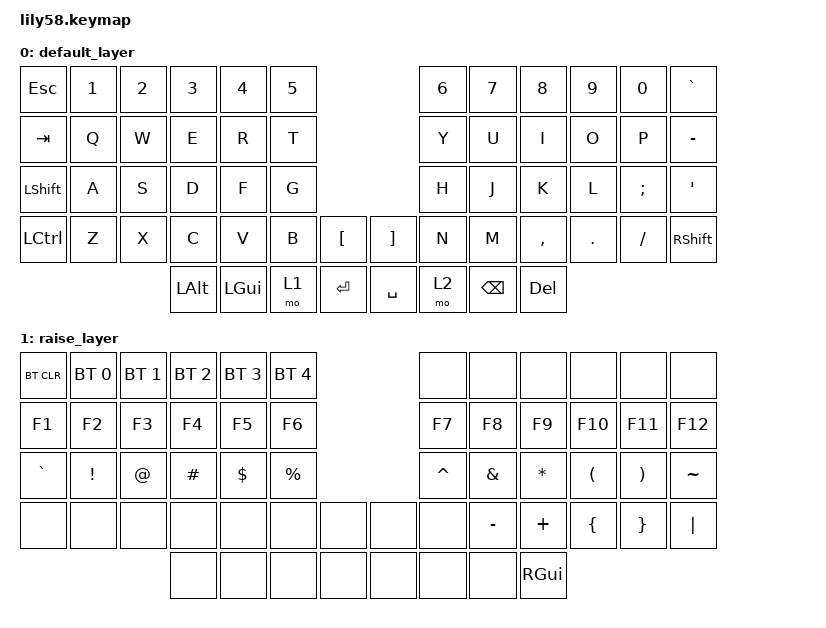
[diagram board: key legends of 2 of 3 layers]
/*
 * Copyright (c) 2020 The ZMK Contributors
 *
 * SPDX-License-Identifier: MIT
 */

#include <behaviors.dtsi>
#include <dt-bindings/zmk/keys.h>
#include <dt-bindings/zmk/bt.h>
#include <dt-bindings/zmk/ext_power.h>
// https://zmk.dev/docs/keymaps/list-of-keycodes

/ {
macros {
        zed_em_kay: zed_em_kay {
            compatible = "zmk,behavior-macro";
            #binding-cells = <0>;
            bindings
                = <&macro_press &kp LSHFT>
                , <&macro_tap &kp Z &kp M &kp K>
                , <&macro_release &kp LSHFT>
                ;
        };
    };




    keymap {
        compatible = "zmk,keymap";

        default_layer {
// ------------------------------------------------------------------------------------------------------------
// |  ESC  |  1  |  2  |  3   |  4   |  5   |                   |  6   |  7    |  8    |  9   |   0   |   `   |
// |  TAB  |  Q  |  W  |  E   |  R   |  T   |                   |  Y   |  U    |  I    |  O   |   P   |   -   |
// | SHIFT |  A  |  S  |  D   |  F   |  G   |                   |  H   |  J    |  K    |  L   |   ;   |   '   |
// |  CTRL |  Z  |  X  |  C   |  V   |  B   |   "["  |  |  "]"  |  N   |  M    |  ,    |  .   |   /   | SHIFT |
//                     | ALT  | GUI  | LOWER|  ENTER |  | SPACE | RAISE| BSPC  | DEL   |
            bindings = <
&kp ESC   &kp N1 &kp N2 &kp N3   &kp N4   &kp N5                     &kp N6 &kp N7   &kp N8    &kp N9  &kp N0   &kp GRAVE
&kp TAB   &kp Q  &kp W  &kp E    &kp R    &kp T                      &kp Y  &kp U    &kp I     &kp O   &kp P    &kp MINUS
&kp LSHFT &kp A  &kp S  &kp D    &kp F    &kp G                      &kp H  &kp J    &kp K     &kp L   &kp SEMI &kp SQT
&kp LCTRL &kp Z  &kp X  &kp C    &kp V    &kp B  &kp LBKT &kp RBKT   &kp N  &kp M    &kp COMMA &kp DOT &kp FSLH &kp RSHFT
                        &kp LALT &kp LGUI &mo 1  &kp RET  &kp SPACE  &mo 2  &kp BSPC &kp DEL
            >;

            sensor-bindings = <&inc_dec_kp C_VOL_UP C_VOL_DN>;
        };

        raise_layer {
// ------------------------------------------------------------------------------------------------------------
// | BTCLR | BT1 | BT2 |  BT3 |  BT4 |  BT5 |                   |      |       |       |      |       |       |
// |  F1   |  F2 |  F3 |  F4  |  F5  |  F6  |                   |  F7  |  F8   |  F9   |  F10 |  F11  |  F12  |
// |   `   |  !  |  @  |  #   |  $   |  %   |                   |  ^   |  &    |  *    |  (   |   )   |   ~   |
// |  CAPS |     |     |      |      |      |        |  |       |      |  _    |  +    |  {   |   }   |  "|"  |
//                     |      |      |      |        |  |       |      |       |  GUI  |
            bindings = <
&bt BT_CLR &bt BT_SEL 0     &bt BT_SEL 1      &bt BT_SEL 2      &bt BT_SEL 3 &bt BT_SEL 4                 &none     &none     &none     &none     &none     &none
&kp F1     &kp F2           &kp F3            &kp F4            &kp F5       &kp F6                       &kp F7    &kp F8    &kp F9    &kp F10   &kp F11   &kp F12
&kp GRAVE  &kp EXCL         &kp AT            &kp HASH          &kp DOLLAR   &kp PRCNT                    &kp CARET &kp AMPS  &kp ASTRK &kp LPAR  &kp RPAR  &kp TILDE
&none      &none            &none             &none             &none        &none       &none   &none    &none     &kp MINUS &kp PLUS  &kp LBRC  &kp RBRC  &kp PIPE
                                              &none             &none        &none       &none   &none    &none     &none     &kp RGUI
            >;

            sensor-bindings = <&inc_dec_kp C_VOL_UP C_VOL_DN>;
        };

        lower_layer {
// ------------------------------------------------------------------------------------------------------------
// |       |     |     |      |      |      |                   |      |       |   /   |  *   |   -   |       |
// | CAP_W |     |     |  ^   |      |      |                   |      |   7   |   8   |  9   |   +   |       |
// |  ZMK  | ZMK!| <-  |  v   |  ->  |      |                   |      |   4   |   5   |  6   |   +   |       |
// |       |     |     |      |      |      |        |  |       |      |   1   |   2   |  3   |       |       |
//                     |      |      |      |        |  |       |      |   0   |   .   |  
            bindings = <
&none       &none   &none   &none     &none    &none                     &none      &none      &kp KP_DIVIDE &kp KP_MULTIPLY   &kp KP_MINUS    &none
&caps_word  &none   &none   &kp UP    &none    &none                     &none      &kp KP_N7  &kp KP_N8     &kp KP_N9         &kp KP_PLUS     &none
&zed_em_kay >, <&kp Z &kp M &kp K &kp EXCLAMATION>, < &kp LEFT &kp DOWN  &kp RIGHT &none                     &none      &kp KP_N4  &kp KP_N5  &kp KP_N6   &kp KP_PLUS &none
&none       &none   &none   &none     &none    &none    &none  &none   &none    &kp KP_N1  &kp KP_N2    &kp KP_N3   &none   &none
                            &none    &none    &none  &none   &none    &none      &kp KP_N0    &kp KP_DOT
            >;

            sensor-bindings = <&inc_dec_kp C_VOL_UP C_VOL_DN>;
        };
    };
};
